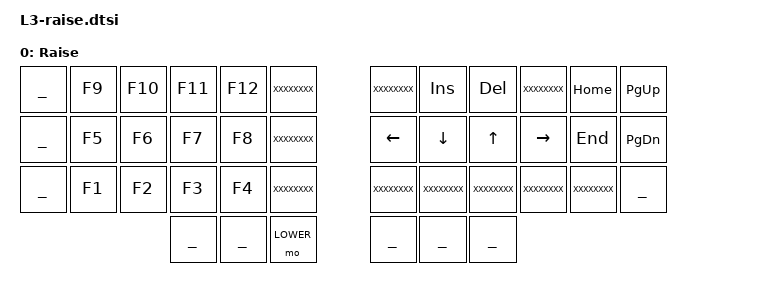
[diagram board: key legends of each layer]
/**
 * Numeric,
 */

/ {
  keymap {
    compatible = "zmk,keymap";

	raise_layer {
		label = "Raise";
		bindings = <
// ╭───────────────┬───────────────┬───────────────┬───────────────┬───────────────┬───────────────╮   ╭───────────────┬───────────────┬───────────────┬───────────────┬───────────────┬───────────────╮
//  0               1               2               3               4               5                   6               7               8               9               10              11
	________        &kp F9        	&kp F10        	&kp F11        	&kp F12        	XXXXXXXX            XXXXXXXX        &kp INS        	&kp DEL        	XXXXXXXX        &kp HOME       	&kp PG_UP
// ├───────────────├───────────────┼───────────────┼───────────────┼───────────────┼───────────────┤   ├───────────────├───────────────┼───────────────┼───────────────┼───────────────┼───────────────┤
//  12              13              14              15              16              17                  18              19              20              21              22              23
	________        &kp F5        	&kp F6        	&kp F7        	&kp F8        	XXXXXXXX            &kp LEFT        &kp DOWN        &kp UP        	&kp RIGHT       &kp END       	&kp PG_DN
// ├───────────────├───────────────┼───────────────┼───────────────┼───────────────┼───────────────┤   ├───────────────├───────────────┼───────────────┼───────────────┼───────────────┼───────────────┤
//  24              25              26              27              28              29                  30              31              32              33              34              35
	________        &kp F1        	&kp F2        	&kp F3        	&kp F4        	XXXXXXXX       		XXXXXXXX   		XXXXXXXX        XXXXXXXX        XXXXXXXX        XXXXXXXX        ________
// ╰───────────────┴───────────────┴───────────────┼───────────────┼───────────────┼───────────────┤   ├───────────────├───────────────┼───────────────┼───────────────┴───────────────┴───────────────╯
//                                                  36              37              38                  39              40              41
                                    	            ________       	________        &mo LOWER           ________		________        ________
//                                                 ╰───────────────┴───────────────┴───────────────╯   ╰───────────────┴───────────────┴───────────────╯
			>;
		};

  };
};
